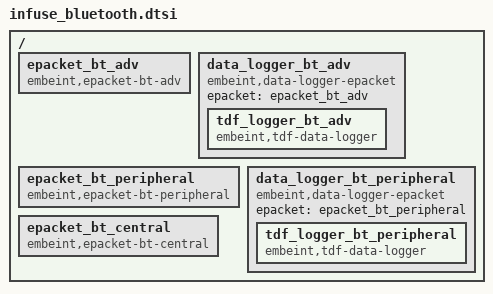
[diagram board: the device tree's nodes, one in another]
/*
 * Copyright (c) 2025 Embeint Holdings Pty Ltd
 * SPDX-License-Identifier: FSL-1.1-ALv2
 */

/ {
	epacket_bt_adv: epacket_bt_adv {
		compatible = "embeint,epacket-bt-adv";
	};

	data_logger_bt_adv: data_logger_bt_adv {
		compatible = "embeint,data-logger-epacket", "embeint,data-logger";
		epacket = <&epacket_bt_adv>;

		tdf_logger_bt_adv: tdf_logger_bt_adv {
			compatible = "embeint,tdf-data-logger";
		};
	};

	epacket_bt_peripheral: epacket_bt_peripheral {
		compatible = "embeint,epacket-bt-peripheral";
	};

	data_logger_bt_peripheral: data_logger_bt_peripheral {
		compatible = "embeint,data-logger-epacket", "embeint,data-logger";
		epacket = <&epacket_bt_peripheral>;

		tdf_logger_bt_peripheral: tdf_logger_bt_peripheral {
			compatible = "embeint,tdf-data-logger";
		};
	};

	epacket_bt_central: epacket_bt_central {
		compatible = "embeint,epacket-bt-central";
	};
};
